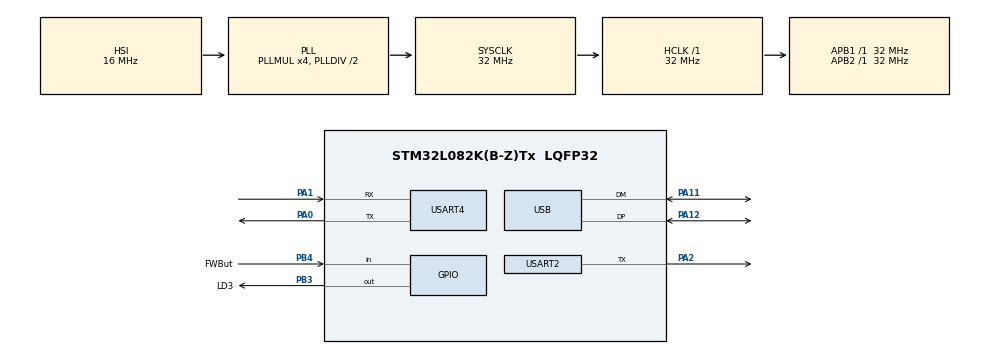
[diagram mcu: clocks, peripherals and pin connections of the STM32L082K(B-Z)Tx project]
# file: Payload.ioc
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Mcu.Family=STM32L0
Mcu.Name=STM32L082K(B-Z)Tx
Mcu.Package=LQFP32
NVIC.TIM2_IRQn=true\:0\:0\:false\:false\:true
NVIC.TimeBase=TIM2_IRQn
NVIC.TimeBaseIP=TIM2
NVIC.USART4_5_IRQn=true\:0\:0\:false\:false\:true
NVIC.USB_IRQn=true\:0\:0\:false\:false\:true
PA0.Mode=Asynchronous
PA0.Signal=USART4_TX
PA1.Mode=Asynchronous
PA1.Signal=USART4_RX
PA11.Mode=Device
PA11.Signal=USB_DM
PA12.Mode=Device
PA12.Signal=USB_DP
PA13.Mode=Serial_Wire
PA13.Signal=SYS_SWDIO
PA14.Mode=Serial_Wire
PA14.Signal=SYS_SWCLK
PA2.Mode=Half_duplex(single_wire_mode)
PA2.Signal=USART2_TX
PB3.GPIO_Label=LD3
PB3.Signal=GPIO_Output
PB4.GPIO_Label=FWBut
PB4.Signal=GPIO_Input
PC14-OSC32_IN.Mode=LSE-External-Oscillator
PC14-OSC32_IN.Signal=RCC_OSC32_IN
PC15-OSC32_OUT.Mode=LSE-External-Oscillator
PC15-OSC32_OUT.Signal=RCC_OSC32_OUT
ProjectManager.HeapSize=0x1000
ProjectManager.StackSize=0x1000
ProjectManager.TargetToolchain=TrueSTUDIO
RCC.AHBFreq_Value=32000000
RCC.APB1Freq_Value=32000000
RCC.APB1TimFreq_Value=32000000
RCC.APB2Freq_Value=32000000
RCC.APB2TimFreq_Value=32000000
RCC.HCLKFreq_Value=32000000
RCC.HSI16_VALUE=16000000
RCC.HSI48MClockSelection=RCC_USBCLKSOURCE_HSI48
RCC.HSI48_VALUE=48000000
RCC.HSI_VALUE=16000000
RCC.MSI_VALUE=2097000
RCC.PLLMUL=RCC_PLLMUL_4
RCC.PLLSourceVirtual=RCC_PLLSOURCE_HSI
RCC.RCC_PERIPHCLK_USART1Var=RCC_PERIPHCLK_USART1
RCC.RTCClockSelection=RCC_RTCCLKSOURCE_LSE
RCC.SYSCLKFreq_VALUE=32000000
RCC.SYSCLKSource=RCC_SYSCLKSOURCE_PLLCLK
RCC.VCOOutputFreq_Value=64000000
USART2.Mode=MODE_TX
USART2.VirtualMode-Half_duplex(single_wire_mode)=VM_ASYNC
USART2.WordLength=WORDLENGTH_8B
USART4.VirtualMode-Asynchronous=VM_ASYNC
USART4.WordLength=WORDLENGTH_8B
USB_DEVICE.CLASS_NAME_FS=CDC
USB_DEVICE.VirtualMode=Cdc
USB_DEVICE.VirtualModeFS=Cdc_FS
VP_AES_VS_AES.Mode=AES_Activate
VP_RNG_VS_RNG.Mode=RNG_Activate
VP_RTC_VS_RTC_Activate.Mode=RTC_Enabled
VP_SYS_VS_tim2.Mode=TIM2
VP_USB_DEVICE_VS_USB_DEVICE_CDC_FS.Mode=CDC_FS
board=Payload

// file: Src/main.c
/**
  ******************************************************************************
  * File Name          : main.c
  * Description        : Main program body
  ******************************************************************************
  * This notice applies to any and all portions of this file
  * that are not between comment pairs USER CODE BEGIN and
  * USER CODE END. Other portions of this file, whether
  * inserted by the user or by software development tools
  * are owned by their respective copyright owners.
  *
  * Copyright (c) 2017 STMicroelectronics International N.V.
  * All rights reserved.
  *
  * Redistribution and use in source and binary forms, with or without
  * modification, are permitted, provided that the following conditions are met:
  *
  * 1. Redistribution of source code must retain the above copyright notice,
  *    this list of conditions and the following disclaimer.
  * 2. Redistributions in binary form must reproduce the above copyright notice,
  *    this list of conditions and the following disclaimer in the documentation
  *    and/or other materials provided with the distribution.
  * 3. Neither the name of STMicroelectronics nor the names of other
  *    contributors to this software may be used to endorse or promote products
  *    derived from this software without specific written permission.
  * 4. This software, including modifications and/or derivative works of this
  *    software, must execute solely and exclusively on microcontroller or
  *    microprocessor devices manufactured by or for STMicroelectronics.
  * 5. Redistribution and use of this software other than as permitted under
  *    this license is void and will automatically terminate your rights under
  *    this license.
  *
  * THIS SOFTWARE IS PROVIDED BY STMICROELECTRONICS AND CONTRIBUTORS "AS IS"
  * AND ANY EXPRESS, IMPLIED OR STATUTORY WARRANTIES, INCLUDING, BUT NOT
  * LIMITED TO, THE IMPLIED WARRANTIES OF MERCHANTABILITY, FITNESS FOR A
  * PARTICULAR PURPOSE AND NON-INFRINGEMENT OF THIRD PARTY INTELLECTUAL PROPERTY
  * RIGHTS ARE DISCLAIMED TO THE FULLEST EXTENT PERMITTED BY LAW. IN NO EVENT
  * SHALL STMICROELECTRONICS OR CONTRIBUTORS BE LIABLE FOR ANY DIRECT, INDIRECT,
  * INCIDENTAL, SPECIAL, EXEMPLARY, OR CONSEQUENTIAL DAMAGES (INCLUDING, BUT NOT
  * LIMITED TO, PROCUREMENT OF SUBSTITUTE GOODS OR SERVICES; LOSS OF USE, DATA,
  * OR PROFITS; OR BUSINESS INTERRUPTION) HOWEVER CAUSED AND ON ANY THEORY OF
  * LIABILITY, WHETHER IN CONTRACT, STRICT LIABILITY, OR TORT (INCLUDING
  * NEGLIGENCE OR OTHERWISE) ARISING IN ANY WAY OUT OF THE USE OF THIS SOFTWARE,
  * EVEN IF ADVISED OF THE POSSIBILITY OF SUCH DAMAGE.
  *
  ******************************************************************************
  */
#include "main.h"
#include "stm32l0xx_hal.h"
#include "usb_device.h"

/* USER CODE BEGIN Includes */
#include "DiceCore.h"

/* USER CODE END Includes */

CRYP_HandleTypeDef hcryp;

RNG_HandleTypeDef hrng;

RTC_HandleTypeDef hrtc;

UART_HandleTypeDef huart2;
UART_HandleTypeDef huart4;

/* USER CODE BEGIN PV */
/* Private variables ---------------------------------------------------------*/

/* USER CODE END PV */

void SystemClock_Config(void);
static void MX_GPIO_Init(void);
static void MX_RNG_Init(void);
static void MX_RTC_Init(void);
static void MX_USART2_UART_Init(void);
static void MX_USART4_UART_Init(void);
static void MX_AES_Init(void);

/* USER CODE BEGIN PFP */
/* Private function prototypes -----------------------------------------------*/

/* USER CODE END PFP */

int main(void)
{

  /* MCU Configuration----------------------------------------------------------*/

  /* Reset of all peripherals, Initializes the Flash interface and the Systick. */
  HAL_Init();

  /* Configure the system clock */
  SystemClock_Config();

  /* Initialize all configured peripherals */
  MX_GPIO_Init();
  MX_RNG_Init();
  MX_RTC_Init();
  MX_USART2_UART_Init();
  MX_USB_DEVICE_Init();
  MX_USART4_UART_Init();
  MX_AES_Init();

  EPRINTF("==========================\r\n");
  EPRINTF("    DICE APP: Payload!\r\n");
  EPRINTF("==========================\r\n");
  EPRINTF("DICE Certificate Bag(%lu):\r\n%s\r\n", DICERAMAREA->info.certBagLen, DICERAMAREA->info.certBag);

  /* Infinite loop */
  while (1)
  {

  /* USER CODE BEGIN 3 */
      if(HAL_GPIO_ReadPin(FWBut_GPIO_Port, FWBut_Pin) != GPIO_PIN_RESET)
      {
          HAL_GPIO_TogglePin(LD3_GPIO_Port, LD3_Pin);
          while(HAL_GPIO_ReadPin(FWBut_GPIO_Port, FWBut_Pin) != GPIO_PIN_RESET);
          HAL_Delay(100);
      }

  }
  /* USER CODE END 3 */

}

/** System Clock Configuration
*/
void SystemClock_Config(void)
{

  RCC_OscInitTypeDef RCC_OscInitStruct;
  RCC_ClkInitTypeDef RCC_ClkInitStruct;
  RCC_PeriphCLKInitTypeDef PeriphClkInit;

    /**Configure the main internal regulator output voltage
    */
  __HAL_PWR_VOLTAGESCALING_CONFIG(PWR_REGULATOR_VOLTAGE_SCALE1);

    /**Configure LSE Drive Capability
    */
  __HAL_RCC_LSEDRIVE_CONFIG(RCC_LSEDRIVE_LOW);

    /**Initializes the CPU, AHB and APB busses clocks
    */
  RCC_OscInitStruct.OscillatorType = RCC_OSCILLATORTYPE_HSI|RCC_OSCILLATORTYPE_LSE
                              |RCC_OSCILLATORTYPE_HSI48;
  RCC_OscInitStruct.LSEState = RCC_LSE_ON;
  RCC_OscInitStruct.HSIState = RCC_HSI_ON;
  RCC_OscInitStruct.HSICalibrationValue = 16;
  RCC_OscInitStruct.HSI48State = RCC_HSI48_ON;
  RCC_OscInitStruct.PLL.PLLState = RCC_PLL_ON;
  RCC_OscInitStruct.PLL.PLLSource = RCC_PLLSOURCE_HSI;
  RCC_OscInitStruct.PLL.PLLMUL = RCC_PLLMUL_4;
  RCC_OscInitStruct.PLL.PLLDIV = RCC_PLLDIV_2;
  if (HAL_RCC_OscConfig(&RCC_OscInitStruct) != HAL_OK)
  {
    _Error_Handler(__FILE__, __LINE__);
  }

    /**Initializes the CPU, AHB and APB busses clocks
    */
  RCC_ClkInitStruct.ClockType = RCC_CLOCKTYPE_HCLK|RCC_CLOCKTYPE_SYSCLK
                              |RCC_CLOCKTYPE_PCLK1|RCC_CLOCKTYPE_PCLK2;
  RCC_ClkInitStruct.SYSCLKSource = RCC_SYSCLKSOURCE_PLLCLK;
  RCC_ClkInitStruct.AHBCLKDivider = RCC_SYSCLK_DIV1;
  RCC_ClkInitStruct.APB1CLKDivider = RCC_HCLK_DIV1;
  RCC_ClkInitStruct.APB2CLKDivider = RCC_HCLK_DIV1;

  if (HAL_RCC_ClockConfig(&RCC_ClkInitStruct, FLASH_LATENCY_1) != HAL_OK)
  {
    _Error_Handler(__FILE__, __LINE__);
  }

  PeriphClkInit.PeriphClockSelection = RCC_PERIPHCLK_USART1|RCC_PERIPHCLK_USART2
                              |RCC_PERIPHCLK_RTC|RCC_PERIPHCLK_USB;
  PeriphClkInit.Usart2ClockSelection = RCC_USART2CLKSOURCE_PCLK1;
  PeriphClkInit.RTCClockSelection = RCC_RTCCLKSOURCE_LSE;
  PeriphClkInit.UsbClockSelection = RCC_USBCLKSOURCE_HSI48;
  if (HAL_RCCEx_PeriphCLKConfig(&PeriphClkInit) != HAL_OK)
  {
    _Error_Handler(__FILE__, __LINE__);
  }

    /**Configure the Systick interrupt time
    */
  HAL_SYSTICK_Config(HAL_RCC_GetHCLKFreq()/1000);

    /**Configure the Systick
    */
  HAL_SYSTICK_CLKSourceConfig(SYSTICK_CLKSOURCE_HCLK);

  /* SysTick_IRQn interrupt configuration */
  HAL_NVIC_SetPriority(SysTick_IRQn, 0, 0);
}

/* AES init function */
static void MX_AES_Init(void)
{

   uint8_t pKey[16] ;

  hcryp.Instance = AES;
  hcryp.Init.DataType = CRYP_DATATYPE_32B;
  pKey[0] = 0x00;
  pKey[1] = 0x00;
  pKey[2] = 0x00;
  pKey[3] = 0x00;
  pKey[4] = 0x00;
  pKey[5] = 0x00;
  pKey[6] = 0x00;
  pKey[7] = 0x00;
  pKey[8] = 0x00;
  pKey[9] = 0x00;
  pKey[10] = 0x00;
  pKey[11] = 0x00;
  pKey[12] = 0x00;
  pKey[13] = 0x00;
  pKey[14] = 0x00;
  pKey[15] = 0x00;
  hcryp.Init.pKey = &pKey[0];
  if (HAL_CRYP_Init(&hcryp) != HAL_OK)
  {
    _Error_Handler(__FILE__, __LINE__);
  }

}

/* RNG init function */
static void MX_RNG_Init(void)
{

  hrng.Instance = RNG;
  if (HAL_RNG_Init(&hrng) != HAL_OK)
  {
    _Error_Handler(__FILE__, __LINE__);
  }

}

/* RTC init function */
static void MX_RTC_Init(void)
{

    /**Initialize RTC Only
    */
  hrtc.Instance = RTC;
  hrtc.Init.HourFormat = RTC_HOURFORMAT_24;
  hrtc.Init.AsynchPrediv = 127;
  hrtc.Init.SynchPrediv = 255;
  hrtc.Init.OutPut = RTC_OUTPUT_DISABLE;
  hrtc.Init.OutPutRemap = RTC_OUTPUT_REMAP_NONE;
  hrtc.Init.OutPutPolarity = RTC_OUTPUT_POLARITY_HIGH;
  hrtc.Init.OutPutType = RTC_OUTPUT_TYPE_OPENDRAIN;
  if (HAL_RTC_Init(&hrtc) != HAL_OK)
  {
    _Error_Handler(__FILE__, __LINE__);
  }

}

/* USART2 init function */
static void MX_USART2_UART_Init(void)
{

  huart2.Instance = USART2;
  huart2.Init.BaudRate = 115200;
  huart2.Init.WordLength = UART_WORDLENGTH_8B;
  huart2.Init.StopBits = UART_STOPBITS_1;
  huart2.Init.Parity = UART_PARITY_NONE;
  huart2.Init.Mode = UART_MODE_TX;
  huart2.Init.HwFlowCtl = UART_HWCONTROL_NONE;
  huart2.Init.OverSampling = UART_OVERSAMPLING_16;
  huart2.Init.OneBitSampling = UART_ONE_BIT_SAMPLE_DISABLE;
  huart2.AdvancedInit.AdvFeatureInit = UART_ADVFEATURE_NO_INIT;
  if (HAL_HalfDuplex_Init(&huart2) != HAL_OK)
  {
    _Error_Handler(__FILE__, __LINE__);
  }

}

/* USART4 init function */
static void MX_USART4_UART_Init(void)
{

  huart4.Instance = USART4;
  huart4.Init.BaudRate = 115200;
  huart4.Init.WordLength = UART_WORDLENGTH_8B;
  huart4.Init.StopBits = UART_STOPBITS_1;
  huart4.Init.Parity = UART_PARITY_NONE;
  huart4.Init.Mode = UART_MODE_TX_RX;
  huart4.Init.HwFlowCtl = UART_HWCONTROL_NONE;
  huart4.Init.OverSampling = UART_OVERSAMPLING_16;
  huart4.Init.OneBitSampling = UART_ONE_BIT_SAMPLE_DISABLE;
  huart4.AdvancedInit.AdvFeatureInit = UART_ADVFEATURE_NO_INIT;
  if (HAL_UART_Init(&huart4) != HAL_OK)
  {
    _Error_Handler(__FILE__, __LINE__);
  }

}

/** Configure pins as
        * Analog
        * Input
        * Output
        * EVENT_OUT
        * EXTI
*/
static void MX_GPIO_Init(void)
{

  GPIO_InitTypeDef GPIO_InitStruct;

  /* GPIO Ports Clock Enable */
  __HAL_RCC_GPIOC_CLK_ENABLE();
  __HAL_RCC_GPIOA_CLK_ENABLE();
  __HAL_RCC_GPIOB_CLK_ENABLE();

  /*Configure GPIO pin Output Level */
  HAL_GPIO_WritePin(LD3_GPIO_Port, LD3_Pin, GPIO_PIN_RESET);

  /*Configure GPIO pin : LD3_Pin */
  GPIO_InitStruct.Pin = LD3_Pin;
  GPIO_InitStruct.Mode = GPIO_MODE_OUTPUT_PP;
  GPIO_InitStruct.Pull = GPIO_NOPULL;
  GPIO_InitStruct.Speed = GPIO_SPEED_FREQ_LOW;
  HAL_GPIO_Init(LD3_GPIO_Port, &GPIO_InitStruct);

  /*Configure GPIO pin : FWBut_Pin */
  GPIO_InitStruct.Pin = FWBut_Pin;
  GPIO_InitStruct.Mode = GPIO_MODE_INPUT;
  GPIO_InitStruct.Pull = GPIO_NOPULL;
  HAL_GPIO_Init(FWBut_GPIO_Port, &GPIO_InitStruct);

}

void HAL_TIM_PeriodElapsedCallback(TIM_HandleTypeDef *htim)
{
  if (htim->Instance == TIM2) {
    HAL_IncTick();
  }
}

void _Error_Handler(char * file, int line)
{
  while(1)
  {
  }
}

/************************ (C) COPYRIGHT STMicroelectronics *****END OF FILE****/
